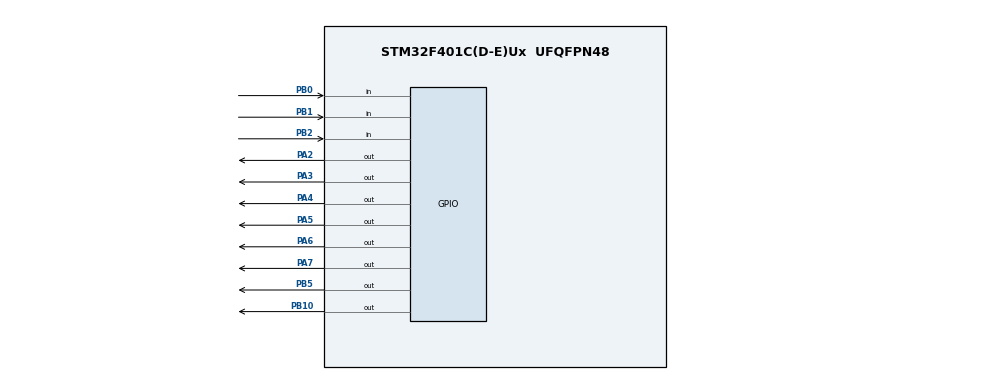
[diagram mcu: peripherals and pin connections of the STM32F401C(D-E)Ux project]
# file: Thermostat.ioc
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Mcu.Family=STM32F4
Mcu.Name=STM32F401C(D-E)Ux
Mcu.Package=UFQFPN48
NVIC.PriorityGroup=NVIC_PRIORITYGROUP_4
PA2.GPIO_PuPd=GPIO_PULLUP
PA2.PinState=GPIO_PIN_SET
PA2.Signal=GPIO_Output
PA3.GPIO_ModeDefaultOutputPP=GPIO_MODE_OUTPUT_PP
PA3.GPIO_PuPd=GPIO_PULLUP
PA3.PinState=GPIO_PIN_SET
PA3.Signal=GPIO_Output
PA4.GPIO_PuPd=GPIO_PULLUP
PA4.PinState=GPIO_PIN_SET
PA4.Signal=GPIO_Output
PA5.GPIO_PuPd=GPIO_PULLUP
PA5.PinState=GPIO_PIN_SET
PA5.Signal=GPIO_Output
PA6.GPIO_PuPd=GPIO_PULLUP
PA6.PinState=GPIO_PIN_SET
PA6.Signal=GPIO_Output
PA7.GPIO_PuPd=GPIO_PULLUP
PA7.PinState=GPIO_PIN_SET
PA7.Signal=GPIO_Output
PB0.GPIO_PuPd=GPIO_PULLUP
PB0.Signal=GPIO_Input
PB1.GPIO_PuPd=GPIO_PULLUP
PB1.Signal=GPIO_Input
PB10.GPIO_ModeDefaultOutputPP=GPIO_MODE_OUTPUT_OD
PB10.GPIO_PuPd=GPIO_NOPULL
PB10.PinState=GPIO_PIN_SET
PB10.Signal=GPIO_Output
PB2.GPIO_PuPd=GPIO_PULLUP
PB2.Signal=GPIO_Input
PB5.GPIO_PuPd=GPIO_PULLUP
PB5.PinState=GPIO_PIN_SET
PB5.Signal=GPIO_Output
ProjectManager.HeapSize=0x200
ProjectManager.StackSize=0x400
ProjectManager.TargetToolchain=STM32CubeIDE
RCC.AHBFreq_Value=16000000
RCC.APB1Freq_Value=16000000
RCC.APB2Freq_Value=16000000
RCC.CortexFreq_Value=16000000
RCC.HSE_VALUE=25000000
RCC.HSI_VALUE=16000000
RCC.LSE_VALUE=32768
RCC.SYSCLKFreq_VALUE=16000000
RCC.VCOOutputFreq_Value=192000000
board=custom

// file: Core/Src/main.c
/* USER CODE BEGIN Header */
/**
  ******************************************************************************
  * @file           : main.c
  * @brief          : Main program body
  ******************************************************************************
  * @attention
  *
  * Copyright (c) 2026 STMicroelectronics.
  * All rights reserved.
  *
  * This software is licensed under terms that can be found in the LICENSE file
  * in the root directory of this software component.
  * If no LICENSE file comes with this software, it is provided AS-IS.
  *
  ******************************************************************************
  */
/* USER CODE END Header */
#include "main.h"

/* USER CODE BEGIN Includes */
#include "app_main.h"
#include "delay.h"
#include "systick.h"
#include "dio.h"
/* USER CODE END Includes */

void SystemClock_Config(void);
static void MX_GPIO_Init(void);

int main(void)
{

  /* MCU Configuration--------------------------------------------------------*/

  /* Reset of all peripherals, Initializes the Flash interface and the Systick. */
  LL_APB2_GRP1_EnableClock(LL_APB2_GRP1_PERIPH_SYSCFG);
  LL_APB1_GRP1_EnableClock(LL_APB1_GRP1_PERIPH_PWR);

  /* System interrupt init*/
  NVIC_SetPriorityGrouping(NVIC_PRIORITYGROUP_4);

  /* SysTick_IRQn interrupt configuration */
  NVIC_SetPriority(SysTick_IRQn, NVIC_EncodePriority(NVIC_GetPriorityGrouping(),15, 0));

  /* Configure the system clock */
  SystemClock_Config();

  /* USER CODE BEGIN SysInit */
	systick_init(SystemCoreClock);
	delay_init(SystemCoreClock);
  /* USER CODE END SysInit */

  /* Initialize all configured peripherals */
  MX_GPIO_Init();
  /* USER CODE BEGIN 2 */
	app_main_init();
  /* USER CODE END 2 */

  /* Infinite loop */
  /* USER CODE BEGIN WHILE */
  while (1)
  {
	  LL_GPIO_TogglePin(GPIOB, LL_GPIO_PIN_0);
	  app_main_run();
    /* USER CODE END WHILE */

  }
}

void SystemClock_Config(void)
{
  LL_FLASH_SetLatency(LL_FLASH_LATENCY_0);
  while(LL_FLASH_GetLatency()!= LL_FLASH_LATENCY_0)
  {
  }
  LL_PWR_SetRegulVoltageScaling(LL_PWR_REGU_VOLTAGE_SCALE2);
  LL_RCC_HSI_SetCalibTrimming(16);
  LL_RCC_HSI_Enable();

   /* Wait till HSI is ready */
  while(LL_RCC_HSI_IsReady() != 1)
  {

  }
  LL_RCC_SetAHBPrescaler(LL_RCC_SYSCLK_DIV_1);
  LL_RCC_SetAPB1Prescaler(LL_RCC_APB1_DIV_1);
  LL_RCC_SetAPB2Prescaler(LL_RCC_APB2_DIV_1);
  LL_RCC_SetSysClkSource(LL_RCC_SYS_CLKSOURCE_HSI);

   /* Wait till System clock is ready */
  while(LL_RCC_GetSysClkSource() != LL_RCC_SYS_CLKSOURCE_STATUS_HSI)
  {

  }
  LL_Init1msTick(16000000);
  LL_SetSystemCoreClock(16000000);
  LL_RCC_SetTIMPrescaler(LL_RCC_TIM_PRESCALER_TWICE);
}

static void MX_GPIO_Init(void)
{
  LL_GPIO_InitTypeDef GPIO_InitStruct = {0};

  /* GPIO Ports Clock Enable */
  LL_AHB1_GRP1_EnableClock(LL_AHB1_GRP1_PERIPH_GPIOA);
  LL_AHB1_GRP1_EnableClock(LL_AHB1_GRP1_PERIPH_GPIOB);

  /**/
  LL_GPIO_SetOutputPin(GPIOA, LL_GPIO_PIN_2|LL_GPIO_PIN_3|LL_GPIO_PIN_4|LL_GPIO_PIN_5
                          |LL_GPIO_PIN_6|LL_GPIO_PIN_7);

  /**/
  LL_GPIO_SetOutputPin(GPIOB, LL_GPIO_PIN_10|LL_GPIO_PIN_5);

  /**/
  GPIO_InitStruct.Pin = LL_GPIO_PIN_2|LL_GPIO_PIN_3|LL_GPIO_PIN_4|LL_GPIO_PIN_5
                          |LL_GPIO_PIN_6|LL_GPIO_PIN_7;
  GPIO_InitStruct.Mode = LL_GPIO_MODE_OUTPUT;
  GPIO_InitStruct.Speed = LL_GPIO_SPEED_FREQ_LOW;
  GPIO_InitStruct.OutputType = LL_GPIO_OUTPUT_PUSHPULL;
  GPIO_InitStruct.Pull = LL_GPIO_PULL_UP;
  LL_GPIO_Init(GPIOA, &GPIO_InitStruct);

  /**/
  GPIO_InitStruct.Pin = LL_GPIO_PIN_0|LL_GPIO_PIN_1|LL_GPIO_PIN_2;
  GPIO_InitStruct.Mode = LL_GPIO_MODE_INPUT;
  GPIO_InitStruct.Pull = LL_GPIO_PULL_UP;
  LL_GPIO_Init(GPIOB, &GPIO_InitStruct);

  /**/
  GPIO_InitStruct.Pin = LL_GPIO_PIN_10;
  GPIO_InitStruct.Mode = LL_GPIO_MODE_OUTPUT;
  GPIO_InitStruct.Speed = LL_GPIO_SPEED_FREQ_LOW;
  GPIO_InitStruct.OutputType = LL_GPIO_OUTPUT_OPENDRAIN;
  GPIO_InitStruct.Pull = LL_GPIO_PULL_NO;
  LL_GPIO_Init(GPIOB, &GPIO_InitStruct);

  /**/
  GPIO_InitStruct.Pin = LL_GPIO_PIN_5;
  GPIO_InitStruct.Mode = LL_GPIO_MODE_OUTPUT;
  GPIO_InitStruct.Speed = LL_GPIO_SPEED_FREQ_LOW;
  GPIO_InitStruct.OutputType = LL_GPIO_OUTPUT_PUSHPULL;
  GPIO_InitStruct.Pull = LL_GPIO_PULL_UP;
  LL_GPIO_Init(GPIOB, &GPIO_InitStruct);

}

void Error_Handler(void)
{
  __disable_irq();
  while (1)
  {
  }
}
